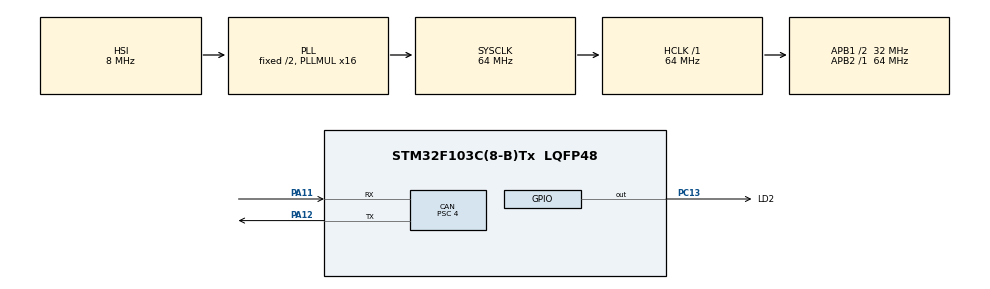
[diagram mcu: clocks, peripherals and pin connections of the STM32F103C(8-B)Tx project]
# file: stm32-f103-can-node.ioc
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ADC1.Channel-2\#ChannelRegularConversion=ADC_CHANNEL_TEMPSENSOR
ADC1.NbrOfConversionFlag=1
ADC1.Rank-2\#ChannelRegularConversion=1
ADC1.SamplingTime-2\#ChannelRegularConversion=ADC_SAMPLETIME_239CYCLES_5
ADC1.master=1
CAN.ABOM=ENABLE
CAN.BS1=CAN_BS1_13TQ
CAN.BS2=CAN_BS2_2TQ
CAN.CalculateBaudRate=500000
CAN.CalculateTimeBit=2000
CAN.CalculateTimeQuantum=125.0
CAN.Mode=CAN_MODE_LOOPBACK
CAN.NART=ENABLE
CAN.Prescaler=4
Mcu.Family=STM32F1
Mcu.Name=STM32F103C(8-B)Tx
Mcu.Package=LQFP48
NVIC.PriorityGroup=NVIC_PRIORITYGROUP_4
PA11.Mode=CAN_Activate
PA11.Signal=CAN_RX
PA12.Mode=CAN_Activate
PA12.Signal=CAN_TX
PA13.Mode=Serial_Wire
PA13.Signal=SYS_JTMS-SWDIO
PA14.Mode=Serial_Wire
PA14.Signal=SYS_JTCK-SWCLK
PC13-TAMPER-RTC.GPIO_Label=LD2
PC13-TAMPER-RTC.Signal=GPIO_Output
ProjectManager.HeapSize=0x200
ProjectManager.StackSize=0x400
ProjectManager.TargetToolchain=STM32CubeIDE
RCC.ADCPresc=RCC_ADCPCLK2_DIV6
RCC.AHBFreq_Value=64000000
RCC.APB1CLKDivider=RCC_HCLK_DIV2
RCC.APB1Freq_Value=32000000
RCC.APB1TimFreq_Value=64000000
RCC.APB2Freq_Value=64000000
RCC.APB2TimFreq_Value=64000000
RCC.HCLKFreq_Value=64000000
RCC.PLLMUL=RCC_PLL_MUL16
RCC.SYSCLKFreq_VALUE=64000000
RCC.SYSCLKSource=RCC_SYSCLKSOURCE_PLLCLK
RCC.USBFreq_Value=64000000
VP_ADC1_TempSens_Input.Mode=IN-TempSens
board=custom

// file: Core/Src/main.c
/* USER CODE BEGIN Header */
/**
  ******************************************************************************
  * @file           : main.c
  * @brief          : Main program body
  ******************************************************************************
  * @attention
  *
  * Copyright (c) 2026 STMicroelectronics.
  * All rights reserved.
  *
  * This software is licensed under terms that can be found in the LICENSE file
  * in the root directory of this software component.
  * If no LICENSE file comes with this software, it is provided AS-IS.
  *
  ******************************************************************************
  */
/* USER CODE END Header */
#include "main.h"

/* USER CODE BEGIN Includes */
#include <stdio.h>

/* USER CODE END Includes */

/* USER CODE BEGIN PD */
#define TEMP_CAN_ID   0x100U    // CAN identifier of the temperature frame
#define V25_MV        1430      // Sensor voltage at 25 degC [mV] (typical, varies per chip)
#define SLOPE_UV      4300      // Sensor slope: 4.3 mV/degC (in uV/degC)
#define VDDA_MV       3300      // ADC reference voltage [mV], assumed to be 3.3 V
#define ADC_SAMPLES   16        // Number of samples averaged per measurement

/* USER CODE END PD */

ADC_HandleTypeDef hadc1;

CAN_HandleTypeDef hcan;

/* USER CODE BEGIN PV */
CAN_TxHeaderTypeDef txHeader;   // CAN frame header (ID, DLC, ...)
uint8_t  txData[3];             // Payload: [0..1] temperature x10 (LE), [2] frame counter
uint32_t txMailbox;             // Mailbox used by the last transmission
uint8_t  counter = 0;           // Frame counter, lets the receiver detect lost frames
/* USER CODE END PV */

void SystemClock_Config(void);
static void MX_GPIO_Init(void);
static void MX_CAN_Init(void);
static void MX_ADC1_Init(void);

/* USER CODE BEGIN 0 */
/**
  * @brief  Configure an accept-all receive filter (filter bank 0, FIFO0).
  *         The node only transmits, but a filter is configured for completeness.
  */
static void CAN_FilterConfig(void)
{
  CAN_FilterTypeDef f = {0};
  f.FilterBank           = 0;
  f.FilterMode           = CAN_FILTERMODE_IDMASK;
  f.FilterScale          = CAN_FILTERSCALE_32BIT;
  f.FilterMaskIdHigh     = 0x0000;      // mask = 0 -> accept every ID
  f.FilterMaskIdLow      = 0x0000;
  f.FilterFIFOAssignment = CAN_RX_FIFO0;
  f.FilterActivation     = ENABLE;
  if (HAL_CAN_ConfigFilter(&hcan, &f) != HAL_OK) Error_Handler();
}

/**
  * @brief  Read the internal temperature sensor (ADC channel 16).
  * @note   The sensor measures the die temperature, not the ambient one.
  *         Absolute accuracy is limited (V25 differs between chips).
  * @retval Temperature in 0.1 degC units, or INT16_MIN on ADC error.
  */
static int16_t read_temp_x10(void)
{
  uint32_t sum = 0, n = 0;

  // Average several conversions to reduce noise
  for (int i = 0; i < ADC_SAMPLES; i++) {
    HAL_ADC_Start(&hadc1);
    if (HAL_ADC_PollForConversion(&hadc1, 10) == HAL_OK) {
      sum += HAL_ADC_GetValue(&hadc1);
      n++;
    }
    HAL_ADC_Stop(&hadc1);
  }
  if (n == 0) return INT16_MIN;                       // no valid conversion

  // Convert raw ADC value (12 bit) to millivolts
  int32_t mv = (int32_t)((sum / n) * VDDA_MV / 4095U);

  // T[degC] = (V25 - Vsense) / slope + 25, computed in 0.1 degC with integers
  int32_t t10 = ((int32_t)V25_MV - mv) * 10000 / SLOPE_UV + 250;
  return (int16_t)t10;
}
/* USER CODE END 0 */

int main(void)
{

  /* MCU Configuration--------------------------------------------------------*/

  /* Reset of all peripherals, Initializes the Flash interface and the Systick. */
  HAL_Init();

  /* Configure the system clock */
  SystemClock_Config();

  /* Initialize all configured peripherals */
  MX_GPIO_Init();
  MX_CAN_Init();
  MX_ADC1_Init();
  /* USER CODE BEGIN 2 */
  HAL_ADCEx_Calibration_Start(&hadc1);                  // ADC self-calibration
  CAN_FilterConfig();
  if (HAL_CAN_Start(&hcan) != HAL_OK) Error_Handler();  // go "on the bus"

  // Static part of the frame header: standard ID, data frame, 3 data bytes
  txHeader.StdId              = TEMP_CAN_ID;
  txHeader.ExtId              = 0;
  txHeader.IDE                = CAN_ID_STD;
  txHeader.RTR                = CAN_RTR_DATA;
  txHeader.DLC                = 3;
  txHeader.TransmitGlobalTime = DISABLE;
  /* USER CODE END 2 */

  /* Infinite loop */
  while (1)
  {

    /* USER CODE BEGIN 3 */
	  int16_t t = read_temp_x10();
	  if (t != INT16_MIN) {
	    uint16_t u = (uint16_t)t;
	    txData[0] = (uint8_t)(u & 0xFF);     // temperature, low byte  (little-endian)
	    txData[1] = (uint8_t)(u >> 8);       // temperature, high byte
	    txData[2] = counter;                 // frame counter

	    // If no node acknowledges the frames, the Tx mailboxes stay occupied.
	    // Abort pending requests so that new frames can be queued.
	    if (HAL_CAN_GetTxMailboxesFreeLevel(&hcan) == 0) {
	      HAL_CAN_AbortTxRequest(&hcan, CAN_TX_MAILBOX0 | CAN_TX_MAILBOX1 | CAN_TX_MAILBOX2);
	    } else if (HAL_CAN_AddTxMessage(&hcan, &txHeader, txData, &txMailbox) == HAL_OK) {
	      HAL_GPIO_TogglePin(LD2_GPIO_Port, LD2_Pin);   // blink LED on each queued frame
	      counter++;
	    }
	  }
	  HAL_Delay(1000);                                  // send one frame per second
	  }
  /* USER CODE END 3 */
}

void SystemClock_Config(void)
{
  RCC_OscInitTypeDef RCC_OscInitStruct = {0};
  RCC_ClkInitTypeDef RCC_ClkInitStruct = {0};
  RCC_PeriphCLKInitTypeDef PeriphClkInit = {0};

  /** Initializes the RCC Oscillators according to the specified parameters
  * in the RCC_OscInitTypeDef structure.
  */
  RCC_OscInitStruct.OscillatorType = RCC_OSCILLATORTYPE_HSI;
  RCC_OscInitStruct.HSIState = RCC_HSI_ON;
  RCC_OscInitStruct.HSICalibrationValue = RCC_HSICALIBRATION_DEFAULT;
  RCC_OscInitStruct.PLL.PLLState = RCC_PLL_ON;
  RCC_OscInitStruct.PLL.PLLSource = RCC_PLLSOURCE_HSI_DIV2;
  RCC_OscInitStruct.PLL.PLLMUL = RCC_PLL_MUL16;
  if (HAL_RCC_OscConfig(&RCC_OscInitStruct) != HAL_OK)
  {
    Error_Handler();
  }

  /** Initializes the CPU, AHB and APB buses clocks
  */
  RCC_ClkInitStruct.ClockType = RCC_CLOCKTYPE_HCLK|RCC_CLOCKTYPE_SYSCLK
                              |RCC_CLOCKTYPE_PCLK1|RCC_CLOCKTYPE_PCLK2;
  RCC_ClkInitStruct.SYSCLKSource = RCC_SYSCLKSOURCE_PLLCLK;
  RCC_ClkInitStruct.AHBCLKDivider = RCC_SYSCLK_DIV1;
  RCC_ClkInitStruct.APB1CLKDivider = RCC_HCLK_DIV2;
  RCC_ClkInitStruct.APB2CLKDivider = RCC_HCLK_DIV1;

  if (HAL_RCC_ClockConfig(&RCC_ClkInitStruct, FLASH_LATENCY_2) != HAL_OK)
  {
    Error_Handler();
  }
  PeriphClkInit.PeriphClockSelection = RCC_PERIPHCLK_ADC;
  PeriphClkInit.AdcClockSelection = RCC_ADCPCLK2_DIV6;
  if (HAL_RCCEx_PeriphCLKConfig(&PeriphClkInit) != HAL_OK)
  {
    Error_Handler();
  }
}

static void MX_ADC1_Init(void)
{

  ADC_ChannelConfTypeDef sConfig = {0};

  /** Common config
  */
  hadc1.Instance = ADC1;
  hadc1.Init.ScanConvMode = ADC_SCAN_DISABLE;
  hadc1.Init.ContinuousConvMode = DISABLE;
  hadc1.Init.DiscontinuousConvMode = DISABLE;
  hadc1.Init.ExternalTrigConv = ADC_SOFTWARE_START;
  hadc1.Init.DataAlign = ADC_DATAALIGN_RIGHT;
  hadc1.Init.NbrOfConversion = 1;
  if (HAL_ADC_Init(&hadc1) != HAL_OK)
  {
    Error_Handler();
  }

  /** Configure Regular Channel
  */
  sConfig.Channel = ADC_CHANNEL_TEMPSENSOR;
  sConfig.Rank = ADC_REGULAR_RANK_1;
  sConfig.SamplingTime = ADC_SAMPLETIME_239CYCLES_5;
  if (HAL_ADC_ConfigChannel(&hadc1, &sConfig) != HAL_OK)
  {
    Error_Handler();
  }

}

static void MX_CAN_Init(void)
{

  hcan.Instance = CAN1;
  hcan.Init.Prescaler = 4;
  hcan.Init.Mode = CAN_MODE_LOOPBACK;
  hcan.Init.SyncJumpWidth = CAN_SJW_1TQ;
  hcan.Init.TimeSeg1 = CAN_BS1_13TQ;
  hcan.Init.TimeSeg2 = CAN_BS2_2TQ;
  hcan.Init.TimeTriggeredMode = DISABLE;
  hcan.Init.AutoBusOff = ENABLE;
  hcan.Init.AutoWakeUp = DISABLE;
  hcan.Init.AutoRetransmission = ENABLE;
  hcan.Init.ReceiveFifoLocked = DISABLE;
  hcan.Init.TransmitFifoPriority = DISABLE;
  if (HAL_CAN_Init(&hcan) != HAL_OK)
  {
    Error_Handler();
  }

}

static void MX_GPIO_Init(void)
{
  GPIO_InitTypeDef GPIO_InitStruct = {0};

  /* GPIO Ports Clock Enable */
  __HAL_RCC_GPIOC_CLK_ENABLE();
  __HAL_RCC_GPIOA_CLK_ENABLE();

  /*Configure GPIO pin Output Level */
  HAL_GPIO_WritePin(LD2_GPIO_Port, LD2_Pin, GPIO_PIN_RESET);

  /*Configure GPIO pin : LD2_Pin */
  GPIO_InitStruct.Pin = LD2_Pin;
  GPIO_InitStruct.Mode = GPIO_MODE_OUTPUT_PP;
  GPIO_InitStruct.Pull = GPIO_NOPULL;
  GPIO_InitStruct.Speed = GPIO_SPEED_FREQ_LOW;
  HAL_GPIO_Init(LD2_GPIO_Port, &GPIO_InitStruct);

}

void Error_Handler(void)
{
  __disable_irq();
  while (1)
  {
  }
}
